VERSION ""

NS_ :

BS_:

BU_: XXX

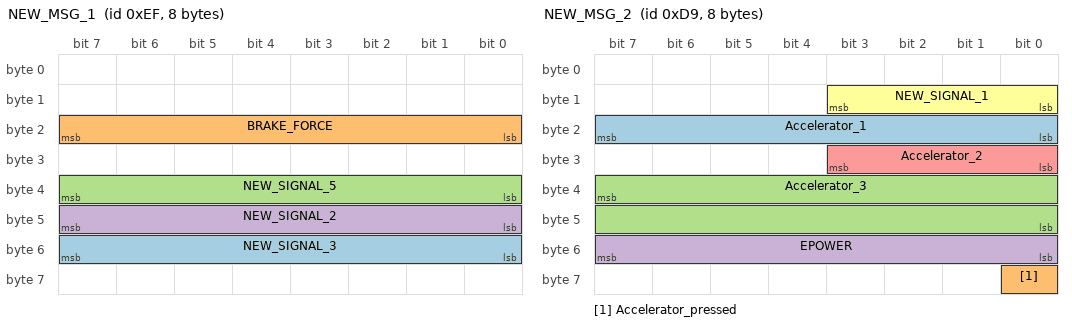
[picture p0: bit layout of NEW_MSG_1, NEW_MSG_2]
BO_ 239 NEW_MSG_1: 8 XXX
 SG_ NEW_SIGNAL_3 : 55|8@0+ (1,0) [0|255] "" XXX
 SG_ BRAKE_FORCE : 16|8@1+ (1,0) [0|255] "" XXX
 SG_ NEW_SIGNAL_5 : 39|8@0+ (1,0) [0|255] "" XXX
 SG_ NEW_SIGNAL_2 : 47|8@0+ (1,0) [0|255] "" XXX

BO_ 217 NEW_MSG_2: 8 XXX
 SG_ Accelerator_1 : 23|8@0+ (1,0) [0|255] "" XXX
 SG_ Accelerator_pressed : 56|1@1+ (1,0) [0|255] "" XXX
 SG_ Accelerator_3 : 39|16@0+ (1,0) [0|65535] "" XXX
 SG_ EPOWER : 48|8@1+ (1,0) [0|255] "" XXX
 SG_ Accelerator_2 : 24|4@1+ (1,0) [0|255] "" XXX
 SG_ NEW_SIGNAL_1 : 8|4@1+ (1,0) [0|15] "" XXX

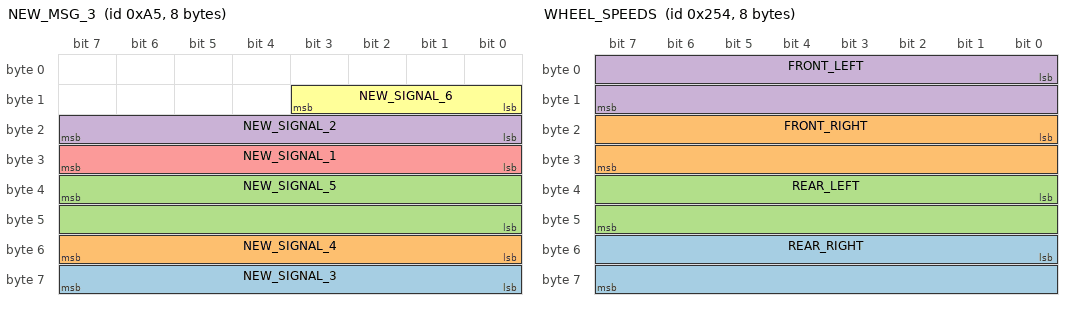
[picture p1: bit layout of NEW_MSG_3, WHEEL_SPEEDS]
BO_ 165 NEW_MSG_3: 8 XXX
 SG_ NEW_SIGNAL_3 : 56|8@1+ (1,0) [0|255] "" XXX
 SG_ NEW_SIGNAL_4 : 48|8@1+ (1,0) [0|255] "" XXX
 SG_ NEW_SIGNAL_5 : 39|16@0+ (1,0) [0|65535] "" XXX
 SG_ NEW_SIGNAL_2 : 16|8@1+ (1,0) [0|65535] "" XXX
 SG_ NEW_SIGNAL_1 : 24|8@1+ (1,0) [0|255] "" XXX
 SG_ NEW_SIGNAL_6 : 8|4@1+ (1,0) [0|15] "" XXX

BO_ 596 WHEEL_SPEEDS: 8 XXX
 SG_ REAR_RIGHT : 48|16@1+ (1,-32767) [0|65535] "" XXX
 SG_ FRONT_RIGHT : 16|16@1+ (1,-32767) [0|255] "" XXX
 SG_ REAR_LEFT : 32|16@1+ (1,-32767) [0|65535] "" XXX
 SG_ FRONT_LEFT : 0|16@1+ (1,-32767) [0|65535] "" XXX

BO_ 407 MAYBE_GEAR_SELECTOR: 8 XXX
 SG_ NEW_SIGNAL_1 : 0|16@1+ (1,0) [0|65535] "" XXX

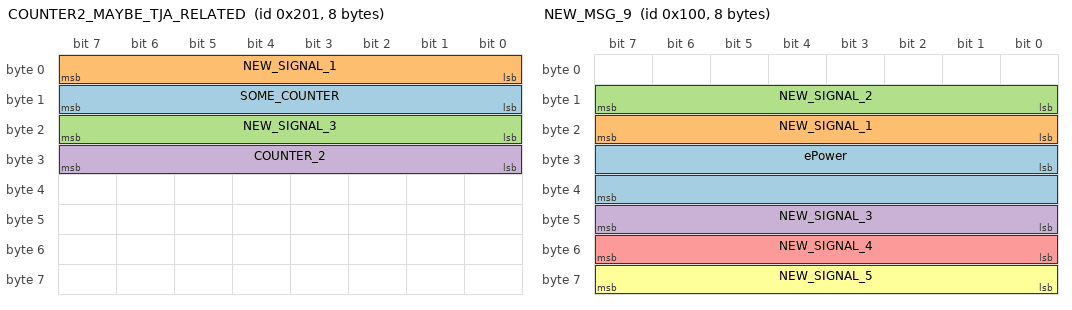
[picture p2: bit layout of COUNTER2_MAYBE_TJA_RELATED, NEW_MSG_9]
BO_ 513 COUNTER2_MAYBE_TJA_RELATED: 8 XXX
 SG_ SOME_COUNTER : 15|8@0+ (1,0) [0|255] "" XXX
 SG_ NEW_SIGNAL_1 : 0|8@1+ (1,0) [0|255] "" XXX
 SG_ NEW_SIGNAL_3 : 16|8@1+ (1,0) [0|255] "" XXX
 SG_ COUNTER_2 : 31|8@0+ (1,0) [0|255] "" XXX

BO_ 518 BRAKE_SOMETHING: 8 XXX
 SG_ NEW_SIGNAL_3 : 23|8@0+ (1,0) [0|255] "" XXX

BO_ 709 MAYBE_Y_ACCELEROMETER: 8 XXX
 SG_ NEW_SIGNAL_2 : 16|16@1+ (1,0) [0|65535] "" XXX
 SG_ NEW_SIGNAL_1 : 15|8@0+ (1,0) [0|255] "" XXX

BO_ 256 NEW_MSG_9: 8 XXX
 SG_ ePower : 24|16@1+ (1,0) [0|255] "" XXX
 SG_ NEW_SIGNAL_1 : 16|8@1+ (1,0) [0|255] "" XXX
 SG_ NEW_SIGNAL_2 : 8|8@1+ (1,0) [0|255] "" XXX
 SG_ NEW_SIGNAL_3 : 40|8@1+ (1,0) [0|255] "" XXX
 SG_ NEW_SIGNAL_4 : 48|8@1+ (1,0) [0|255] "" XXX
 SG_ NEW_SIGNAL_5 : 56|8@1+ (1,0) [0|255] "" XXX

BO_ 417 CAR_SPEED: 8 XXX
 SG_ SPEED : 16|16@1+ (0.015625,0) [0|65535] "KPH" XXX

BO_ 770 STEERING_ANGLE: 8 XXX
 SG_ STEERING_ANGLE : 16|16@1+ (0.002747,-90) [0|65535] "DEG" XXX

BO_ 817 NEW_MSG_4: 8 XXX

BO_ 464 NEW_MSG_12: 8 XXX
 SG_ SOME_COUNTER : 0|16@1+ (1,0) [0|65535] "" XXX

BO_ 772 NEW_MSG_13: 8 XXX
 SG_ INTERESTING : 16|16@1+ (1,0) [0|65535] "" XXX

BO_ 883 NEW_MSG_14: 8 XXX
 SG_ NEW_SIGNAL_1 : 0|16@1+ (1,0) [0|255] "" XXX

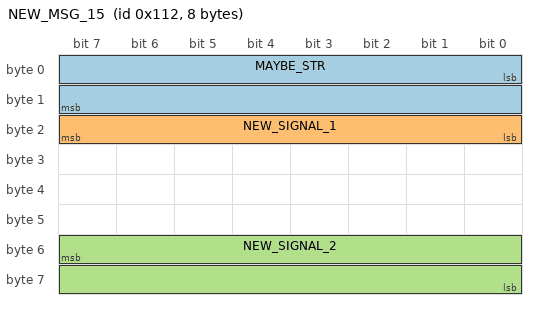
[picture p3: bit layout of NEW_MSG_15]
BO_ 274 NEW_MSG_15: 8 XXX
 SG_ MAYBE_STR : 0|16@1+ (1,0) [0|65535] "" XXX
 SG_ NEW_SIGNAL_1 : 16|8@1+ (1,0) [0|255] "" XXX
 SG_ NEW_SIGNAL_2 : 55|16@0+ (1,0) [0|65535] "" XXX

BO_ 769 NEW_MSG_16: 8 XXX
 SG_ STEER_ANGLE : 16|16@1+ (1,0) [0|65535] "" XXX

BO_ 779 NEW_MSG_17: 8 XXX
 SG_ COUNTER : 0|16@1+ (1,0) [0|65535] "" XXX

BO_ 415 STEER_ANGLE: 8 XXX
 SG_ ANGLE : 16|16@1+ (1,0) [0|65535] "" XXX

BO_ 410 STEER_ANGLE_RATE: 8 XXX
 SG_ RATE : 16|16@1+ (0.1,-3250) [0|65535] "DEG/S" XXX

BO_ 409 STEER_TORQUE: 8 XXX
 SG_ TORQUE : 16|16@1+ (1,-32767) [0|65535] "" XXX

BO_ 502 SIGNAL_BLINKING_ACTIVE: 8 XXX
 SG_ TURN_INDICATORS : 7|8@0+ (1,0) [0|255] "" XXX

BO_ 150 Z_AXIS_ACCEL: 8 XXX
 SG_ NEW_SIGNAL_1 : 0|16@1+ (1,-98) [0|65535] "" XXX

BO_ 243 NEW_MSG_18: 8 XXX

BO_ 494 TURN_INDICATORS: 8 XXX
 SG_ INDICATOR_STALK : 0|8@1+ (1,0) [0|255] "" XXX

BO_ 600 IN_MOTION_YESNO: 8 XXX
 SG_ NEW_SIGNAL_1 : 0|8@1+ (1,0) [0|255] "" XXX

BO_ 355 NEW_MSG_20: 8 XXX
 SG_ NEW_SIGNAL_1 : 16|16@1+ (1,0) [0|65535] "" XXX

BO_ 678 NEW_MSG_21: 8 XXX
 SG_ SOME_COUNTER : 15|8@0+ (1,0) [0|255] "" XXX

BO_ 808 NEW_MSG_22: 8 XXX
 SG_ NEW_SIGNAL_1 : 8|8@1+ (1,0) [0|255] "" XXX
 SG_ COUNTER : 0|8@1+ (1,0) [0|255] "" XXX

BO_ 841 NEW_MSG_23: 8 XXX
 SG_ NEW_SIGNAL_1 : 16|16@1+ (1,-5680) [0|255] "" XXX

BO_ 652 NEW_MSG_24: 8 XXX
 SG_ NEW_SIGNAL_1 : 0|8@1+ (1,0) [0|255] "" XXX

BO_ 512 SOMETHING_BRAKES: 8 XXX
 SG_ NEW_SIGNAL_1 : 23|7@0+ (1,0) [0|127] "" XXX
 SG_ NEW_SIGNAL_2 : 7|24@0+ (1,0) [0|16777215] "" XXX

BO_ 514 NEW_MSG_25: 8 XXX
 SG_ NEW_SIGNAL_1 : 7|16@0+ (1,0) [0|65535] "" XXX

BO_ 408 ANOTHER_COUNTER: 8 XXX
 SG_ NEW_SIGNAL_1 : 15|8@0+ (1,0) [0|255] "" XXX

BO_ 152 WAVEFORM: 8 XXX
 SG_ NEW_SIGNAL_1 : 7|16@0+ (1,0) [0|65535] "" XXX

BO_ 1528 MAYBE_BRAKE_PRESSURE: 8 XXX
 SG_ NEW_SIGNAL_2 : 31|40@0+ (1,0) [0|1099511627775] "" XXX
 SG_ NEW_SIGNAL_1 : 15|8@0+ (1,0) [0|255] "" XXX

BO_ 1504 NEW_MSG_26: 8 XXX

BO_ 1344 MAYBE_ACCELEROMETER: 8 XXX
 SG_ NEW_SIGNAL_1 : 39|16@0+ (1,0) [0|65535] "" XXX

BO_ 1068 NO_CLUE: 8 XXX
 SG_ NEW_SIGNAL_1 : 7|16@0+ (1,0) [0|65535] "" XXX

BO_ 1017 WAVEFORM2: 8 XXX
 SG_ NEW_SIGNAL_1 : 7|16@0+ (1,0) [0|65535] "" XXX

BO_ 632 EXACT_SAME_PLOT_AS_NO_CLUE: 8 XXX
 SG_ NEW_SIGNAL_1 : 7|16@0+ (1,0) [0|65535] "" XXX

BO_ 1982 SOMETHING_STREAMING_HERE: 8 XXX

BO_ 679 NEW_MSG_5: 8 XXX
 SG_ NEW_SIGNAL_1 : 7|8@0+ (1,0) [0|255] "" XXX
 SG_ NEW_SIGNAL_2 : 15|8@0+ (1,0) [0|255] "" XXX

BO_ 781 NEW_MSG_6: 8 XXX
 SG_ NEW_SIGNAL_1 : 7|8@0+ (1,0) [0|255] "" XXX

BO_ 878 NEW_MSG_8: 8 XXX
 SG_ NEW_SIGNAL_1 : 0|8@1+ (1,0) [0|255] "" XXX

BO_ 879 NEW_MSG_10: 8 XXX
 SG_ NEW_SIGNAL_1 : 7|8@0+ (1,0) [0|255] "" XXX

BO_ 761 NEW_MSG_11: 8 XXX
 SG_ NEW_SIGNAL_1 : 32|8@1+ (1,0) [0|255] "" XXX

BO_ 807 COUNTER: 8 XXX
 SG_ NEW_SIGNAL_1 : 7|8@0+ (1,0) [0|255] "" XXX

BO_ 840 SOMETHING_TODO_WITH_MOVEMENT: 8 XXX
 SG_ NEW_SIGNAL_1 : 7|16@0+ (1,0) [0|65535] "" XXX

BO_ 743 NEW_MSG_19: 8 XXX
 SG_ NEW_SIGNAL_1 : 7|16@0+ (1,0) [0|255] "" XXX

BO_ 749 WAVEFORM_ANDCOUNTER: 8 XXX
 SG_ NEW_SIGNAL_1 : 7|8@0+ (1,0) [0|255] "" XXX
 SG_ NEW_SIGNAL_2 : 15|8@0+ (1,0) [0|255] "" XXX

BO_ 842 MOVEMENT_RELATED: 8 XXX
 SG_ NEW_SIGNAL_1 : 7|8@0+ (1,0) [0|255] "" XXX

BO_ 844 NEW_MSG_27: 8 XXX
 SG_ NEW_SIGNAL_1 : 23|8@0+ (1,0) [0|255] "" XXX

BO_ 935 NEW_MSG_28: 8 XXX
 SG_ NEW_SIGNAL_1 : 7|8@0+ (1,0) [0|255] "" XXX
 SG_ NEW_SIGNAL_2 : 8|8@1+ (1,0) [0|255] "" XXX

BO_ 910 SOMETHING_SPEED: 8 XXX
 SG_ NEW_SIGNAL_1 : 15|16@0+ (1,0) [0|4294967295] "" XXX
